VERSION "K24_Common"

NS_ :

BS_:

BU_: PCM UNKNOWN

BO_ 316 PCM_0x13C: 8 PCM
 SG_ TORQUE_ESTIMATE : 7|16@0- (1,0) [-32768|32767] "raw"  UNKNOWN
 SG_ TORQUE_TARGET : 23|16@0- (1,0) [-32768|32767] "raw"  UNKNOWN
 SG_ ACCELERATOR_REQUEST : 32|8@1+ (0.39215686274509803,0) [0|100] "%"  UNKNOWN
 SG_ TORQUE_STATE : 40|2@1+ (1,0) [0|3] ""  UNKNOWN
 SG_ RSVD_1 : 42|2@1+ (1,0) [0|3] ""  UNKNOWN
 SG_ UNKNOWN_1 : 44|1@1+ (1,0) [0|1] ""  UNKNOWN
 SG_ FRAME_1AA_WINDOW_LATCH : 45|1@1+ (1,0) [0|1] ""  UNKNOWN
 SG_ START_PHASE_LATCH : 46|1@1+ (1,0) [0|1] ""  UNKNOWN
 SG_ DTC_STATUS_7_LATCH : 47|1@1+ (1,0) [0|1] ""  UNKNOWN
 SG_ STOP_CONTACT_GUARD : 48|1@1+ (1,0) [0|1] ""  UNKNOWN
 SG_ RSVD_3 : 49|1@1+ (1,0) [0|1] ""  UNKNOWN
 SG_ CLUTCH_PEDAL_POSITION_SWITCH_B_STATUS : 50|1@1+ (1,0) [0|1] ""  UNKNOWN
 SG_ RSVD_4 : 51|5@1+ (1,0) [0|31] ""  UNKNOWN
 SG_ CHECKSUM : 56|4@1+ (1,0) [0|15] ""  UNKNOWN
 SG_ COUNTER : 60|2@1+ (1,0) [0|3] ""  UNKNOWN
 SG_ INITIALIZED_STATUS : 62|1@1+ (1,0) [0|1] ""  UNKNOWN
 SG_ FRAME_1AA_INVALID_OR_FALLBACK_STATE_TBD : 63|1@1+ (1,0) [0|1] ""  UNKNOWN
VAL_ 316 CLUTCH_PEDAL_POSITION_SWITCH_B_STATUS 0 "OPEN" 1 "CLOSE" ;
VAL_ 316 TORQUE_STATE 0 "NORMAL" 1 "VSA_CONTROL_CANDIDATE" 2 "FUEL_CUT" 3 "UNKNOWN" ;

CM_ SG_ 316 CLUTCH_PEDAL_POSITION_SWITCH_B_STATUS "CANFI: Clutch Pedal Position Switch B Status";
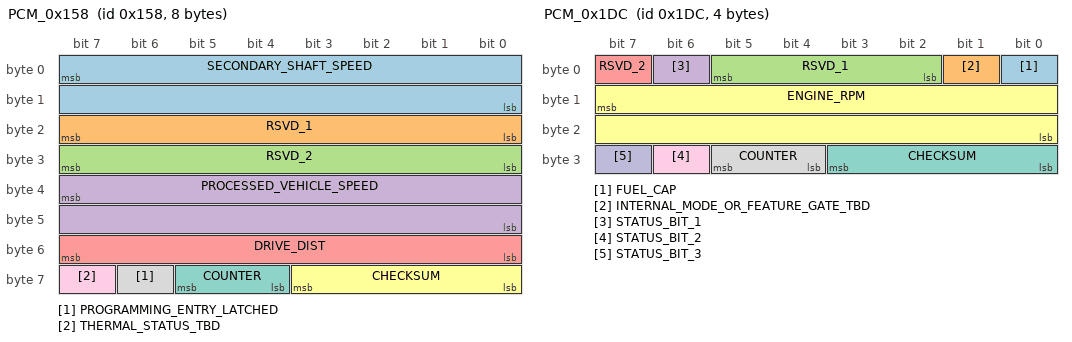
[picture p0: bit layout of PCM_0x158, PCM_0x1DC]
BO_ 344 PCM_0x158: 8 PCM
 SG_ SECONDARY_SHAFT_SPEED : 7|16@0+ (0.01,0) [0|655.35] "km/h"  UNKNOWN
 SG_ RSVD_1 : 16|8@1+ (1,0) [0|255] ""  UNKNOWN
 SG_ RSVD_2 : 24|8@1+ (1,0) [0|255] ""  UNKNOWN
 SG_ PROCESSED_VEHICLE_SPEED : 39|16@0+ (0.01,0) [0|655.35] "km/h"  UNKNOWN
 SG_ DRIVE_DIST : 48|8@1+ (10,0) [0|2550] "m"  UNKNOWN
 SG_ CHECKSUM : 56|4@1+ (1,0) [0|15] ""  UNKNOWN
 SG_ COUNTER : 60|2@1+ (1,0) [0|3] ""  UNKNOWN
 SG_ PROGRAMMING_ENTRY_LATCHED : 62|1@1+ (1,0) [0|1] ""  UNKNOWN
 SG_ THERMAL_STATUS_TBD : 63|1@1+ (1,0) [0|1] ""  UNKNOWN

CM_ SG_ 344 DRIVE_DIST "CANFI: Drive Dist";
BO_ 380 PCM_0x17C: 8 PCM
 SG_ ACCELERATOR_PEDAL_POSITION : 0|8@1+ (0.39215686274509803,0) [0|100] "%"  UNKNOWN
 SG_ THROTTLE_ABOVE_IDLE : 8|8@1+ (0.4,0) [0|102] "deg"  UNKNOWN
 SG_ ENGINE_SPEED : 23|16@0+ (1,0) [0|65535] "rpm"  UNKNOWN
 SG_ BRAKE_SWITCH : 32|1@1+ (1,0) [0|1] ""  UNKNOWN
 SG_ CRUISE_CANCEL_EVENT : 33|1@1+ (1,0) [0|1] ""  UNKNOWN
 SG_ CRUISE_FAULT_SPEED_INHIBIT : 34|1@1+ (1,0) [0|1] ""  UNKNOWN
 SG_ CRUISE_ENGAGED : 35|1@1+ (1,0) [0|1] ""  UNKNOWN
 SG_ MIL : 36|1@1+ (1,0) [0|1] ""  UNKNOWN
 SG_ MIL_STATUS : 37|1@1+ (1,0) [0|1] ""  UNKNOWN
 SG_ CRUISE_INDICATOR : 38|1@1+ (1,0) [0|1] ""  UNKNOWN
 SG_ GAS_PEDAL_PRESSED : 39|1@1+ (1,0) [0|1] ""  UNKNOWN
 SG_ RSVD_1 : 40|1@1+ (1,0) [0|1] ""  UNKNOWN
 SG_ APPLICATION_STATUS_ASSERTED : 41|1@1+ (1,0) [0|1] ""  UNKNOWN
 SG_ ACCEL_PEDAL_FAULT : 42|1@1+ (1,0) [0|1] ""  UNKNOWN
 SG_ RSVD_2 : 43|2@1+ (1,0) [0|3] ""  UNKNOWN
 SG_ IDLE_STOP_PRIMARY_CONTROL : 45|1@1+ (1,0) [0|1] ""  UNKNOWN
 SG_ IDLE_STOP_CST_CONTRIBUTION : 46|1@1+ (1,0) [0|1] ""  UNKNOWN
 SG_ ENGINE_IDLE_STOP_MODE_CONTROL : 47|1@1+ (1,0) [0|1] ""  UNKNOWN
 SG_ RSVD_3 : 48|5@1+ (1,0) [0|31] ""  UNKNOWN
 SG_ CRUISE_BRAKE_SW_IDLE_STOP_SW : 53|1@1+ (1,0) [0|1] ""  UNKNOWN
 SG_ CRUISE_TRANS_REQUEST_WIRE : 54|2@1+ (1,0) [0|3] ""  UNKNOWN
 SG_ CHECKSUM : 56|4@1+ (1,0) [0|15] ""  UNKNOWN
 SG_ COUNTER : 60|2@1+ (1,0) [0|3] ""  UNKNOWN
 SG_ RSVD_4 : 62|1@1+ (1,0) [0|1] ""  UNKNOWN
 SG_ FIWARN : 63|1@1+ (1,0) [0|1] ""  UNKNOWN
VAL_ 380 CRUISE_BRAKE_SW_IDLE_STOP_SW 0 "CLOSE" 1 "OPEN" ;
VAL_ 380 ENGINE_IDLE_STOP_MODE_CONTROL 0 "UNCONTROLLED" 1 "CONTROLLED" ;
VAL_ 380 CRUISE_INDICATOR 0 "OFF" 1 "ON" ;
VAL_ 380 MIL_STATUS 0 "OFF" 1 "ON" ;
VAL_ 380 MIL 0 "OFF" 1 "ON" ;
VAL_ 380 BRAKE_SWITCH 0 "OFF" 1 "ON" ;

CM_ SG_ 380 ENGINE_SPEED "CANFI: Engine Speed";
CM_ SG_ 380 BRAKE_SWITCH "CANFI: Brake Switch";
CM_ SG_ 380 MIL "CANFI: MIL";
CM_ SG_ 380 MIL_STATUS "CANFI: MIL Status";
CM_ SG_ 380 CRUISE_INDICATOR "CANFI: Cruise Indicator";
CM_ SG_ 380 CRUISE_BRAKE_SW_IDLE_STOP_SW "CANFI: Cruise Brake Sw/Idle Stop Sw";
CM_ SG_ 380 ENGINE_IDLE_STOP_MODE_CONTROL "CANFI: Engine Idle Stop Mode Control";
CM_ SG_ 380 FIWARN "CANFI: FIWARN";
BO_ 476 PCM_0x1DC: 4 PCM
 SG_ FUEL_CAP : 0|1@1+ (1,0) [0|1] ""  UNKNOWN
 SG_ INTERNAL_MODE_OR_FEATURE_GATE_TBD : 1|1@1+ (1,0) [0|1] ""  UNKNOWN
 SG_ RSVD_1 : 2|4@1+ (1,0) [0|15] ""  UNKNOWN
 SG_ STATUS_BIT_1 : 6|1@1+ (1,0) [0|1] ""  UNKNOWN
 SG_ RSVD_2 : 7|1@1+ (1,0) [0|1] ""  UNKNOWN
 SG_ ENGINE_RPM : 15|16@0+ (1,0) [0|65535] "rpm"  UNKNOWN
 SG_ CHECKSUM : 24|4@1+ (1,0) [0|15] ""  UNKNOWN
 SG_ COUNTER : 28|2@1+ (1,0) [0|3] ""  UNKNOWN
 SG_ STATUS_BIT_2 : 30|1@1+ (1,0) [0|1] ""  UNKNOWN
 SG_ STATUS_BIT_3 : 31|1@1+ (1,0) [0|1] ""  UNKNOWN
VAL_ 476 FUEL_CAP 0 "CLOSE" 1 "OPEN" ;

CM_ SG_ 476 FUEL_CAP "CANFI: FUEL CAP";
BO_ 800 PCM_0x320: 8 PCM
 SG_ RSVD_1 : 0|6@1+ (1,0) [0|63] ""  UNKNOWN
 SG_ ENGINE_STATE_TBD : 6|2@1+ (1,0) [0|3] ""  UNKNOWN
 SG_ STATUS_BIT_1 : 8|1@1+ (1,0) [0|1] ""  UNKNOWN
 SG_ STATUS_BIT_2 : 9|1@1+ (1,0) [0|1] ""  UNKNOWN
 SG_ RSVD_2 : 10|4@1+ (1,0) [0|15] ""  UNKNOWN
 SG_ I_VTEC_INDICATOR_COMMAND : 14|1@1+ (1,0) [0|1] ""  UNKNOWN
 SG_ RSVD_3 : 15|1@1+ (1,0) [0|1] ""  UNKNOWN
 SG_ UNKNOWN_1 : 16|3@1+ (1,0) [0|7] ""  UNKNOWN
 SG_ UNKNOWN_4 : 19|3@1+ (1,0) [0|7] ""  UNKNOWN
 SG_ STATUS_BIT_3 : 22|1@1+ (1,0) [0|1] ""  UNKNOWN
 SG_ STATUS_BIT_9_TBD : 23|1@1+ (1,0) [0|1] ""  UNKNOWN
 SG_ RSVD_4 : 24|8@1+ (1,0) [0|255] ""  UNKNOWN
 SG_ RSVD_5 : 32|7@1+ (1,0) [0|127] ""  UNKNOWN
 SG_ STATUS_BIT_4 : 39|1@1+ (1,0) [0|1] ""  UNKNOWN
 SG_ UNKNOWN_2 : 40|3@1+ (1,0) [0|7] ""  UNKNOWN
 SG_ UNKNOWN_3 : 43|3@1+ (1,0) [0|7] ""  UNKNOWN
 SG_ UNKNOWN_5 : 46|2@1+ (1,0) [0|3] ""  UNKNOWN
 SG_ STATUS_BIT_5 : 48|1@1+ (1,0) [0|1] ""  UNKNOWN
 SG_ RSVD_6 : 49|2@1+ (1,0) [0|3] ""  UNKNOWN
 SG_ STATUS_BIT_6 : 51|1@1+ (1,0) [0|1] ""  UNKNOWN
 SG_ RSVD_7 : 52|4@1+ (1,0) [0|15] ""  UNKNOWN
 SG_ CHECKSUM : 56|4@1+ (1,0) [0|15] ""  UNKNOWN
 SG_ COUNTER : 60|2@1+ (1,0) [0|3] ""  UNKNOWN
 SG_ STATUS_BIT_7 : 62|1@1+ (1,0) [0|1] ""  UNKNOWN
 SG_ STATUS_BIT_8 : 63|1@1+ (1,0) [0|1] ""  UNKNOWN
VAL_ 800 I_VTEC_INDICATOR_COMMAND 0 "OFF" 1 "ON" ;

CM_ SG_ 800 I_VTEC_INDICATOR_COMMAND "CANFI: i-VTEC Indicator Command";
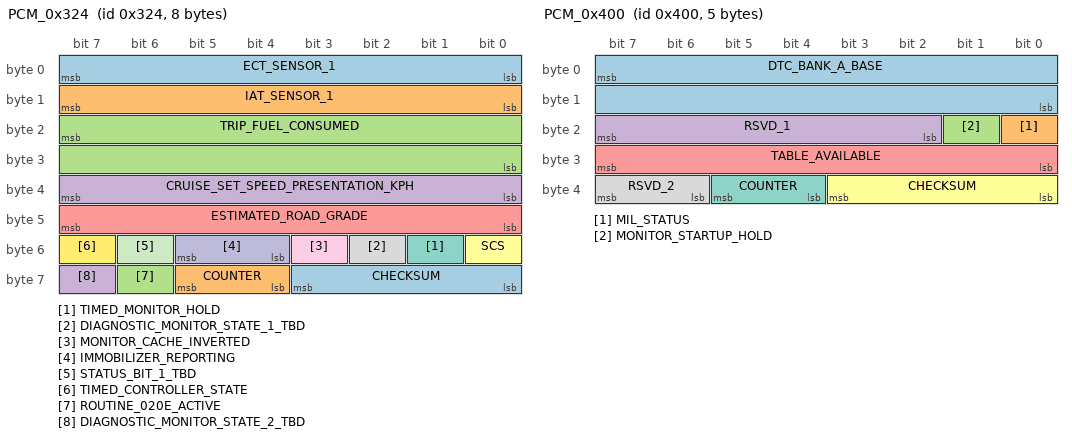
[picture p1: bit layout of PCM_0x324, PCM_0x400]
BO_ 804 PCM_0x324: 8 PCM
 SG_ ECT_SENSOR_1 : 0|8@1+ (1,-40) [-40|215] "degC"  UNKNOWN
 SG_ IAT_SENSOR_1 : 8|8@1+ (1,-40) [-40|215] "degC"  UNKNOWN
 SG_ TRIP_FUEL_CONSUMED : 23|16@0+ (1,0) [0|65535] ""  UNKNOWN
 SG_ CRUISE_SET_SPEED_PRESENTATION_KPH : 32|8@1+ (1,0) [0|255] "km/h"  UNKNOWN
 SG_ ESTIMATED_ROAD_GRADE : 40|8@1- (0.125,0) [-16|15.875] "%"  UNKNOWN
 SG_ SCS : 48|1@1+ (1,0) [0|1] ""  UNKNOWN
 SG_ TIMED_MONITOR_HOLD : 49|1@1+ (1,0) [0|1] ""  UNKNOWN
 SG_ DIAGNOSTIC_MONITOR_STATE_1_TBD : 50|1@1+ (1,0) [0|1] ""  UNKNOWN
 SG_ MONITOR_CACHE_INVERTED : 51|1@1+ (1,0) [0|1] ""  UNKNOWN
 SG_ IMMOBILIZER_REPORTING : 52|2@1+ (1,0) [0|3] ""  UNKNOWN
 SG_ STATUS_BIT_1_TBD : 54|1@1+ (1,0) [0|1] ""  UNKNOWN
 SG_ TIMED_CONTROLLER_STATE : 55|1@1+ (1,0) [0|1] ""  UNKNOWN
 SG_ CHECKSUM : 56|4@1+ (1,0) [0|15] ""  UNKNOWN
 SG_ COUNTER : 60|2@1+ (1,0) [0|3] ""  UNKNOWN
 SG_ ROUTINE_020E_ACTIVE : 62|1@1+ (1,0) [0|1] ""  UNKNOWN
 SG_ DIAGNOSTIC_MONITOR_STATE_2_TBD : 63|1@1+ (1,0) [0|1] ""  UNKNOWN
VAL_ 804 IMMOBILIZER_REPORTING 0 "COMPLETE_ACCEPTED" 1 "INCOMPLETE" 2 "COMPLETE_NOT_ACCEPTED" ;
VAL_ 804 SCS 0 "OPEN" 1 "SHORT" ;
VAL_ 804 IAT_SENSOR_1 255 "INVALID" ;
VAL_ 804 ECT_SENSOR_1 255 "INVALID" ;

CM_ SG_ 804 SCS "CANFI: SCS";
BO_ 808 PCM_0x328: 8 PCM
 SG_ RSVD_1 : 0|8@1+ (1,0) [0|255] ""  UNKNOWN
 SG_ IDLE_STOP_CVT_PREREQUISITE : 8|8@1+ (1,0) [0|255] ""  UNKNOWN
 SG_ RSVD_2 : 16|8@1+ (1,0) [0|255] ""  UNKNOWN
 SG_ RSVD_3 : 24|2@1+ (1,0) [0|3] ""  UNKNOWN
 SG_ STOCK_DISABLED_IDLE_STOP_PREREQUISITE : 26|1@1+ (1,0) [0|1] ""  UNKNOWN
 SG_ RSVD_4 : 27|5@1+ (1,0) [0|31] ""  UNKNOWN
 SG_ RSVD_5 : 32|8@1+ (1,0) [0|255] ""  UNKNOWN
 SG_ RSVD_6 : 40|2@1+ (1,0) [0|3] ""  UNKNOWN
 SG_ THROTTLE_ACTUATOR_SUPPLY_VOLTAGE_OFF_EVENT_TBD : 42|1@1+ (1,0) [0|1] ""  UNKNOWN
 SG_ STATUS_BIT_1 : 43|1@1+ (1,0) [0|1] ""  UNKNOWN
 SG_ SECONDARY_REQUEST_LIMIT_ENABLE : 44|1@1+ (1,0) [0|1] ""  UNKNOWN
 SG_ RSVD_7 : 45|1@1+ (1,0) [0|1] ""  UNKNOWN
 SG_ DISCRETE_INPUT_QUALIFICATION : 46|1@1+ (1,0) [0|1] ""  UNKNOWN
 SG_ STARTUP_QUALIFICATION_COMPLETE : 47|1@1+ (1,0) [0|1] ""  UNKNOWN
 SG_ CRUISE_TRANSITION_REASON : 48|4@1+ (1,0) [0|15] ""  UNKNOWN
 SG_ RSVD_8 : 52|2@1+ (1,0) [0|3] ""  UNKNOWN
 SG_ STATUS_BIT_2 : 54|1@1+ (1,0) [0|1] ""  UNKNOWN
 SG_ RSVD_9 : 55|1@1+ (1,0) [0|1] ""  UNKNOWN
 SG_ CHECKSUM : 56|4@1+ (1,0) [0|15] ""  UNKNOWN
 SG_ COUNTER : 60|2@1+ (1,0) [0|3] ""  UNKNOWN
 SG_ STATUS_BIT_3_TBD : 62|1@1+ (1,0) [0|1] ""  UNKNOWN
 SG_ ACCELERATOR_PEDAL_DUAL_TRACK_FAULT_ANY : 63|1@1+ (1,0) [0|1] ""  UNKNOWN

BO_ 1024 PCM_0x400: 5 PCM
 SG_ DTC_BANK_A_BASE : 7|16@0+ (1,0) [0|65535] ""  UNKNOWN
 SG_ MIL_STATUS : 16|1@1+ (1,0) [0|1] ""  UNKNOWN
 SG_ MONITOR_STARTUP_HOLD : 17|1@1+ (1,0) [0|1] ""  UNKNOWN
 SG_ RSVD_1 : 18|6@1+ (1,0) [0|63] ""  UNKNOWN
 SG_ TABLE_AVAILABLE : 24|8@1+ (1,0) [0|255] ""  UNKNOWN
 SG_ CHECKSUM : 32|4@1+ (1,0) [0|15] ""  UNKNOWN
 SG_ COUNTER : 36|2@1+ (1,0) [0|3] ""  UNKNOWN
 SG_ RSVD_2 : 38|2@1+ (1,0) [0|3] ""  UNKNOWN
VAL_ 1024 MIL_STATUS 0 "OFF" 1 "ON" ;

CM_ SG_ 1024 MIL_STATUS "CANFI: MIL Status";
BO_ 1036 PCM_0x40C: 8 PCM
 SG_ MULTIPLEX_PAGE M : 0|4@1+ (1,0) [0|15] ""  UNKNOWN
 SG_ MULTIPLEX_GROUP : 4|2@1+ (1,0) [0|3] ""  UNKNOWN
 SG_ DIAGNOSTIC_EVENT_STATE : 6|2@1+ (1,0) [0|3] ""  UNKNOWN
 SG_ RSVD_1 m0 : 8|8@1+ (1,0) [0|255] ""  UNKNOWN
 SG_ P01_VIN_CHARACTER_1_B1 m1 : 8|8@1+ (1,0) [0|255] ""  UNKNOWN
 SG_ P02_VIN_CHARACTER_7_B1 m2 : 8|8@1+ (1,0) [0|255] ""  UNKNOWN
 SG_ P03_VIN_CHARACTER_13_B1 m3 : 8|8@1+ (1,0) [0|255] ""  UNKNOWN
 SG_ P04_ECUID1 m4 : 8|8@1+ (1,0) [0|255] ""  UNKNOWN
 SG_ P05_ENGINE_SPEED m5 : 15|16@0+ (0.25,0) [0|16383.75] "rpm"  UNKNOWN
 SG_ P06_IAT_SENSOR_1_V m6 : 8|8@1+ (0.019600000232458115,0.0) [0|4.998000059276819] "V"  UNKNOWN
 SG_ P0B_HO2S_S2 m11 : 16|8@1+ (0.019600000232458115,0.0) [0|4.998000059276819] "V"  UNKNOWN
 SG_ P06_MAP_SENSOR_V m6 : 24|8@1+ (0.019600000232458115,0.0) [0|4.998000059276819] "V"  UNKNOWN
 SG_ P08_TP_SENSOR_A m8 : 24|8@1+ (0.019600000232458115,0.0) [0|4.998000059276819] "V"  UNKNOWN
 SG_ P08_TP_SENSOR_B m8 : 32|8@1+ (0.019600000232458115,0.0) [0|4.998000059276819] "V"  UNKNOWN
 SG_ P0D_MAF_SENSOR m13 : 32|8@1+ (0.019600000232458115,0.0) [0|4.998000059276819] "V"  UNKNOWN
 SG_ P05_ECT_SENSOR_1_V m5 : 40|8@1+ (0.019600000232458115,0.0) [0|4.998000059276819] "V"  UNKNOWN
 SG_ P06_BARO_SENSOR_V m6 : 40|8@1+ (0.019600000232458115,0.0) [0|4.998000059276819] "V"  UNKNOWN
 SG_ P07_APP_SENSOR_A m7 : 40|8@1+ (0.019600000232458115,0.0) [0|4.998000059276819] "V"  UNKNOWN
 SG_ P07_APP_SENSOR_B m7 : 48|8@1+ (0.019600000232458115,0.0) [0|4.998000059276819] "V"  UNKNOWN
 SG_ P07_VEHICLE_SPEED_PCM m7 : 8|8@1+ (1,0) [0|255] "km/h"  UNKNOWN
 SG_ P08_APP_SENSOR m8 : 15|16@0+ (0.005,0) [0|327.675] "%"  UNKNOWN
 SG_ P09_TARGET_TH_VLV m9 : 15|16@0+ (0.005,0) [0|327.675] "deg"  UNKNOWN
 SG_ RSVD_2 m10 : 8|8@1+ (1,0) [0|255] ""  UNKNOWN
 SG_ P0B_FSS m11 : 8|8@1+ (1,0) [0|255] ""  UNKNOWN
 SG_ RSVD_3 m12 : 8|8@1+ (1,0) [0|255] ""  UNKNOWN
 SG_ RSVD_4 m13 : 8|8@1+ (1,0) [0|255] ""  UNKNOWN
 SG_ P0E_MAF_SENSOR m14 : 15|16@0+ (0.01,0) [0|655.35] "g/s"  UNKNOWN
 SG_ P0F_FUEL_LEVEL m15 : 8|8@1+ (0.39215686274509803,0) [0|100] "%"  UNKNOWN
 SG_ P00_DIAGNOSTIC_EVENT_OR_FREEZE_DTC m0 : 23|16@0+ (1,0) [0|65535] ""  UNKNOWN
 SG_ P01_VIN_CHARACTER_2_B2 m1 : 16|8@1+ (1,0) [0|255] ""  UNKNOWN
 SG_ P02_VIN_CHARACTER_8_B2 m2 : 16|8@1+ (1,0) [0|255] ""  UNKNOWN
 SG_ P03_VIN_CHARACTER_14_B2 m3 : 16|8@1+ (1,0) [0|255] ""  UNKNOWN
 SG_ P04_ECUID2 m4 : 16|8@1+ (1,0) [0|255] ""  UNKNOWN
 SG_ P06_IAT_SENSOR_1_DEG_C m6 : 16|8@1+ (1,-40) [-40|215] "degC"  UNKNOWN
 SG_ P07_CLV m7 : 16|8@1+ (0.39215686274509803,0) [0|100] "%"  UNKNOWN
 SG_ RSVD_5 m10 : 16|8@1+ (1,0) [0|255] ""  UNKNOWN
 SG_ RSVD_6 m12 : 16|8@1+ (1,0) [0|255] ""  UNKNOWN
 SG_ P0D_AF_SENSOR m13 : 23|16@0+ (1,0) [0|65535] ""  UNKNOWN
 SG_ RSVD_7 m15 : 16|8@1+ (1,0) [0|255] ""  UNKNOWN
 SG_ P01_VIN_CHARACTER_3_B3 m1 : 24|8@1+ (1,0) [0|255] ""  UNKNOWN
 SG_ P02_VIN_CHARACTER_9_B3 m2 : 24|8@1+ (1,0) [0|255] ""  UNKNOWN
 SG_ P03_VIN_CHARACTER_15_B3 m3 : 24|8@1+ (1,0) [0|255] ""  UNKNOWN
 SG_ P04_ECUID3 m4 : 24|8@1+ (1,0) [0|255] ""  UNKNOWN
 SG_ P05_TP_SENSOR m5 : 24|8@1+ (0.39215686274509803,0) [0|100] "%"  UNKNOWN
 SG_ P07_SPARK_ADVANCE m7 : 24|8@1+ (0.5,-64) [-64|63.5] "deg"  UNKNOWN
 SG_ P09_THROTTLE_AN12_BASELINE m9 : 24|8@1+ (1,0) [0|255] ""  UNKNOWN
 SG_ P0A_AF_LAMBDA m10 : 31|16@0+ (3.0517578125e-05,0) [0|1.999969482421875] "ratio"  UNKNOWN
 SG_ RSVD_8 m11 : 24|8@1+ (1,0) [0|255] ""  UNKNOWN
 SG_ RSVD_9 m12 : 24|8@1+ (1,0) [0|255] ""  UNKNOWN
 SG_ P0E_CMP_CTRL m14 : 24|8@1+ (1,0) [0|255] ""  UNKNOWN
 SG_ RSVD_10 m15 : 24|8@1+ (1,0) [0|255] ""  UNKNOWN
 SG_ P00_FORMAT_OR_LENGTH m0 : 32|8@1+ (1,0) [0|255] ""  UNKNOWN
 SG_ P01_VIN_CHARACTER_4_B4 m1 : 32|8@1+ (1,0) [0|255] ""  UNKNOWN
 SG_ P02_VIN_CHARACTER_10_B4 m2 : 32|8@1+ (1,0) [0|255] ""  UNKNOWN
 SG_ P03_VIN_CHARACTER_16_B4 m3 : 32|8@1+ (1,0) [0|255] ""  UNKNOWN
 SG_ P04_ECUID4 m4 : 32|8@1+ (1,0) [0|255] ""  UNKNOWN
 SG_ P05_REL_TP_SENSOR m5 : 32|8@1+ (0.39215686274509803,0) [0|100] "%"  UNKNOWN
 SG_ P06_MAP_SENSOR_KPA m6 : 32|8@1+ (1,0) [0|255] "kPa"  UNKNOWN
 SG_ P07_CONTROL_MODULE_VOLTAGE_CLAMPED m7 : 32|8@1+ (1,0) [0|255] "raw"  UNKNOWN
 SG_ P09_THROTTLE_AN45_BASELINE m9 : 32|8@1+ (1,0) [0|255] ""  UNKNOWN
 SG_ RSVD_11 m11 : 32|8@1+ (1,0) [0|255] ""  UNKNOWN
 SG_ RSVD_12 m12 : 32|8@1+ (1,0) [0|255] ""  UNKNOWN
 SG_ P0E_ENGINE_RUNTIME m14 : 39|16@0+ (1,0) [0|65535] "s"  UNKNOWN
 SG_ RSVD_13 m15 : 32|8@1+ (1,0) [0|255] ""  UNKNOWN
 SG_ RSVD_14 m0 : 40|8@1+ (1,0) [0|255] ""  UNKNOWN
 SG_ P01_VIN_CHARACTER_5_B5 m1 : 40|8@1+ (1,0) [0|255] ""  UNKNOWN
 SG_ P02_VIN_CHARACTER_11_B5 m2 : 40|8@1+ (1,0) [0|255] ""  UNKNOWN
 SG_ P03_VIN_CHARACTER_17_B5 m3 : 40|8@1+ (1,0) [0|255] ""  UNKNOWN
 SG_ P04_ECUID5 m4 : 40|8@1+ (1,0) [0|255] ""  UNKNOWN
 SG_ P08_THROTTLE_VLV m8 : 47|16@0+ (0.005,0) [0|327.675] "deg"  UNKNOWN
 SG_ P09_IDLE_TARGET_TH m9 : 47|16@0+ (0.005,0) [0|327.675] "deg"  UNKNOWN
 SG_ P0A_AF_FB_ST_FUEL_TRIM m10 : 40|8@1+ (0.0078125,0) [0|1.9921875] "ratio"  UNKNOWN
 SG_ RSVD_15 m11 : 40|8@1+ (1,0) [0|255] ""  UNKNOWN
 SG_ P0C_F_INJECTOR m12 : 47|16@0+ (0.004,0) [0|262.14] "ms"  UNKNOWN
 SG_ P0D_AF_LAMBDA_CMD m13 : 47|16@0+ (3.0517578125e-05,0) [0|1.999969482421875] "ratio"  UNKNOWN
 SG_ RSVD_16 m15 : 40|8@1+ (1,0) [0|255] ""  UNKNOWN
 SG_ RSVD_17 m0 : 48|8@1+ (1,0) [0|255] ""  UNKNOWN
 SG_ P01_VIN_CHARACTER_6_B6 m1 : 48|8@1+ (1,0) [0|255] ""  UNKNOWN
 SG_ P02_VIN_CHARACTER_12_B6 m2 : 48|8@1+ (1,0) [0|255] ""  UNKNOWN
 SG_ P03_IDENTIFICATION_EXTRA_BYTE_TBD m3 : 48|8@1+ (1,0) [0|255] ""  UNKNOWN
 SG_ RSVD_18 m4 : 48|8@1+ (1,0) [0|255] ""  UNKNOWN
 SG_ P05_ECT_SENSOR_1_DEG_C m5 : 48|8@1+ (1,-40) [-40|215] "degC"  UNKNOWN
 SG_ P06_BARO_SENSOR_KPA m6 : 48|8@1+ (1,0) [0|255] "kPa"  UNKNOWN
 SG_ P0A_AF_FB_AVE_LT_FUEL_TRIM m10 : 48|8@1+ (0.0078125,0) [0|1.9921875] "ratio"  UNKNOWN
 SG_ RSVD_19 m11 : 48|8@1+ (1,0) [0|255] ""  UNKNOWN
 SG_ P0E_EVAP_PC_DUTY m14 : 48|8@1+ (0.39215686274509803,0) [0|100] "%"  UNKNOWN
 SG_ RSVD_20 m15 : 48|8@1+ (1,0) [0|255] ""  UNKNOWN
 SG_ CHECKSUM : 56|4@1+ (1,0) [0|15] ""  UNKNOWN
 SG_ COUNTER : 60|2@1+ (1,0) [0|3] ""  UNKNOWN
 SG_ DIAGNOSTIC_STATUS_FLAG_6 m0 : 62|1@1+ (1,0) [0|1] ""  UNKNOWN
 SG_ DIAGNOSTIC_STATUS_FLAG_7 m0 : 63|1@1+ (1,0) [0|1] ""  UNKNOWN
 SG_ RSVD_21 m5 : 62|2@1+ (1,0) [0|3] ""  UNKNOWN
VAL_ 1036 P0B_FSS 0 "NONE" 1 "OL_COND" 2 "CLOSED" 4 "OL_DRV" 8 "OL_DTC" 16 "CL_O2_SX" ;
SG_MUL_VAL_ 1036 RSVD_1 MULTIPLEX_PAGE 0-0;
SG_MUL_VAL_ 1036 P01_VIN_CHARACTER_1_B1 MULTIPLEX_PAGE 1-1;
SG_MUL_VAL_ 1036 P02_VIN_CHARACTER_7_B1 MULTIPLEX_PAGE 2-2;
SG_MUL_VAL_ 1036 P03_VIN_CHARACTER_13_B1 MULTIPLEX_PAGE 3-3;
SG_MUL_VAL_ 1036 P04_ECUID1 MULTIPLEX_PAGE 4-4;
SG_MUL_VAL_ 1036 P05_ENGINE_SPEED MULTIPLEX_PAGE 5-5;
SG_MUL_VAL_ 1036 P07_VEHICLE_SPEED_PCM MULTIPLEX_PAGE 7-7;
SG_MUL_VAL_ 1036 P08_APP_SENSOR MULTIPLEX_PAGE 8-8;
SG_MUL_VAL_ 1036 P09_TARGET_TH_VLV MULTIPLEX_PAGE 9-9;
SG_MUL_VAL_ 1036 RSVD_2 MULTIPLEX_PAGE 10-10;
SG_MUL_VAL_ 1036 P0B_FSS MULTIPLEX_PAGE 11-11;
SG_MUL_VAL_ 1036 RSVD_3 MULTIPLEX_PAGE 12-12;
SG_MUL_VAL_ 1036 RSVD_4 MULTIPLEX_PAGE 13-13;
SG_MUL_VAL_ 1036 P0E_MAF_SENSOR MULTIPLEX_PAGE 14-14;
SG_MUL_VAL_ 1036 P0F_FUEL_LEVEL MULTIPLEX_PAGE 15-15;
SG_MUL_VAL_ 1036 P00_DIAGNOSTIC_EVENT_OR_FREEZE_DTC MULTIPLEX_PAGE 0-0;
SG_MUL_VAL_ 1036 P01_VIN_CHARACTER_2_B2 MULTIPLEX_PAGE 1-1;
SG_MUL_VAL_ 1036 P02_VIN_CHARACTER_8_B2 MULTIPLEX_PAGE 2-2;
SG_MUL_VAL_ 1036 P03_VIN_CHARACTER_14_B2 MULTIPLEX_PAGE 3-3;
SG_MUL_VAL_ 1036 P04_ECUID2 MULTIPLEX_PAGE 4-4;
SG_MUL_VAL_ 1036 P06_IAT_SENSOR_1_DEG_C MULTIPLEX_PAGE 6-6;
SG_MUL_VAL_ 1036 P07_CLV MULTIPLEX_PAGE 7-7;
SG_MUL_VAL_ 1036 RSVD_5 MULTIPLEX_PAGE 10-10;
SG_MUL_VAL_ 1036 RSVD_6 MULTIPLEX_PAGE 12-12;
SG_MUL_VAL_ 1036 P0D_AF_SENSOR MULTIPLEX_PAGE 13-13;
SG_MUL_VAL_ 1036 RSVD_7 MULTIPLEX_PAGE 15-15;
SG_MUL_VAL_ 1036 P01_VIN_CHARACTER_3_B3 MULTIPLEX_PAGE 1-1;
SG_MUL_VAL_ 1036 P02_VIN_CHARACTER_9_B3 MULTIPLEX_PAGE 2-2;
SG_MUL_VAL_ 1036 P03_VIN_CHARACTER_15_B3 MULTIPLEX_PAGE 3-3;
SG_MUL_VAL_ 1036 P04_ECUID3 MULTIPLEX_PAGE 4-4;
SG_MUL_VAL_ 1036 P05_TP_SENSOR MULTIPLEX_PAGE 5-5;
SG_MUL_VAL_ 1036 P07_SPARK_ADVANCE MULTIPLEX_PAGE 7-7;
SG_MUL_VAL_ 1036 P09_THROTTLE_AN12_BASELINE MULTIPLEX_PAGE 9-9;
SG_MUL_VAL_ 1036 P0A_AF_LAMBDA MULTIPLEX_PAGE 10-10;
SG_MUL_VAL_ 1036 RSVD_8 MULTIPLEX_PAGE 11-11;
SG_MUL_VAL_ 1036 RSVD_9 MULTIPLEX_PAGE 12-12;
SG_MUL_VAL_ 1036 P0E_CMP_CTRL MULTIPLEX_PAGE 14-14;
SG_MUL_VAL_ 1036 RSVD_10 MULTIPLEX_PAGE 15-15;
SG_MUL_VAL_ 1036 P00_FORMAT_OR_LENGTH MULTIPLEX_PAGE 0-0;
SG_MUL_VAL_ 1036 P01_VIN_CHARACTER_4_B4 MULTIPLEX_PAGE 1-1;
SG_MUL_VAL_ 1036 P02_VIN_CHARACTER_10_B4 MULTIPLEX_PAGE 2-2;
SG_MUL_VAL_ 1036 P03_VIN_CHARACTER_16_B4 MULTIPLEX_PAGE 3-3;
SG_MUL_VAL_ 1036 P04_ECUID4 MULTIPLEX_PAGE 4-4;
SG_MUL_VAL_ 1036 P05_REL_TP_SENSOR MULTIPLEX_PAGE 5-5;
SG_MUL_VAL_ 1036 P06_MAP_SENSOR_KPA MULTIPLEX_PAGE 6-6;
SG_MUL_VAL_ 1036 P07_CONTROL_MODULE_VOLTAGE_CLAMPED MULTIPLEX_PAGE 7-7;
SG_MUL_VAL_ 1036 P09_THROTTLE_AN45_BASELINE MULTIPLEX_PAGE 9-9;
SG_MUL_VAL_ 1036 RSVD_11 MULTIPLEX_PAGE 11-11;
SG_MUL_VAL_ 1036 RSVD_12 MULTIPLEX_PAGE 12-12;
SG_MUL_VAL_ 1036 P0E_ENGINE_RUNTIME MULTIPLEX_PAGE 14-14;
SG_MUL_VAL_ 1036 RSVD_13 MULTIPLEX_PAGE 15-15;
SG_MUL_VAL_ 1036 RSVD_14 MULTIPLEX_PAGE 0-0;
SG_MUL_VAL_ 1036 P01_VIN_CHARACTER_5_B5 MULTIPLEX_PAGE 1-1;
SG_MUL_VAL_ 1036 P02_VIN_CHARACTER_11_B5 MULTIPLEX_PAGE 2-2;
SG_MUL_VAL_ 1036 P03_VIN_CHARACTER_17_B5 MULTIPLEX_PAGE 3-3;
SG_MUL_VAL_ 1036 P04_ECUID5 MULTIPLEX_PAGE 4-4;
SG_MUL_VAL_ 1036 P08_THROTTLE_VLV MULTIPLEX_PAGE 8-8;
SG_MUL_VAL_ 1036 P09_IDLE_TARGET_TH MULTIPLEX_PAGE 9-9;
SG_MUL_VAL_ 1036 P0A_AF_FB_ST_FUEL_TRIM MULTIPLEX_PAGE 10-10;
SG_MUL_VAL_ 1036 RSVD_15 MULTIPLEX_PAGE 11-11;
SG_MUL_VAL_ 1036 P0C_F_INJECTOR MULTIPLEX_PAGE 12-12;
SG_MUL_VAL_ 1036 P0D_AF_LAMBDA_CMD MULTIPLEX_PAGE 13-13;
SG_MUL_VAL_ 1036 RSVD_16 MULTIPLEX_PAGE 15-15;
SG_MUL_VAL_ 1036 RSVD_17 MULTIPLEX_PAGE 0-0;
SG_MUL_VAL_ 1036 P01_VIN_CHARACTER_6_B6 MULTIPLEX_PAGE 1-1;
SG_MUL_VAL_ 1036 P02_VIN_CHARACTER_12_B6 MULTIPLEX_PAGE 2-2;
SG_MUL_VAL_ 1036 P03_IDENTIFICATION_EXTRA_BYTE_TBD MULTIPLEX_PAGE 3-3;
SG_MUL_VAL_ 1036 RSVD_18 MULTIPLEX_PAGE 4-4;
SG_MUL_VAL_ 1036 P05_ECT_SENSOR_1_DEG_C MULTIPLEX_PAGE 5-5;
SG_MUL_VAL_ 1036 P06_BARO_SENSOR_KPA MULTIPLEX_PAGE 6-6;
SG_MUL_VAL_ 1036 P0A_AF_FB_AVE_LT_FUEL_TRIM MULTIPLEX_PAGE 10-10;
SG_MUL_VAL_ 1036 RSVD_19 MULTIPLEX_PAGE 11-11;
SG_MUL_VAL_ 1036 P0E_EVAP_PC_DUTY MULTIPLEX_PAGE 14-14;
SG_MUL_VAL_ 1036 RSVD_20 MULTIPLEX_PAGE 15-15;

CM_ SG_ 1036 P05_ENGINE_SPEED "CANFI: Engine Speed";
CM_ SG_ 1036 P05_TP_SENSOR "CANFI: TP Sensor";
CM_ SG_ 1036 P05_REL_TP_SENSOR "CANFI: REL TP Sensor";
CM_ SG_ 1036 P05_ECT_SENSOR_1_DEG_C "CANFI: ECT Sensor 1";
CM_ SG_ 1036 P06_IAT_SENSOR_1_DEG_C "CANFI: IAT Sensor (1)";
CM_ SG_ 1036 P06_MAP_SENSOR_KPA "CANFI: MAP Sensor";
CM_ SG_ 1036 P06_BARO_SENSOR_KPA "CANFI: Baro Sensor";
CM_ SG_ 1036 P07_VEHICLE_SPEED_PCM "CANFI: Vehicle Speed(PCM)";
CM_ SG_ 1036 P07_SPARK_ADVANCE "CANFI: Spark Advance";
CM_ SG_ 1036 P08_APP_SENSOR "CANFI: APP Sensor";
CM_ SG_ 1036 P08_THROTTLE_VLV "CANFI: Throttle VLV";
CM_ SG_ 1036 P09_TARGET_TH_VLV "CANFI: Target TH VLV";
CM_ SG_ 1036 P09_IDLE_TARGET_TH "CANFI: Idle Target TH";
CM_ SG_ 1036 P0A_AF_LAMBDA "CANFI: AF Lambda";
CM_ SG_ 1036 P0A_AF_FB_ST_FUEL_TRIM "CANFI: AF FB (ST Fuel Trim)";
CM_ SG_ 1036 P0A_AF_FB_AVE_LT_FUEL_TRIM "CANFI: AF FB AVE (LT Fuel Trim)";
CM_ SG_ 1036 P0C_F_INJECTOR "CANFI: F Injector";
CM_ SG_ 1036 P0D_AF_SENSOR "CANFI: AF Sensor";
CM_ SG_ 1036 P0D_AF_LAMBDA_CMD "CANFI: AF Lambda Cmd";
CM_ SG_ 1036 P0E_MAF_SENSOR "CANFI: MAF Sensor";
CM_ SG_ 1036 P0E_CMP_CTRL "CANFI: CMP Ctrl";
CM_ SG_ 1036 P0E_EVAP_PC_DUTY "CANFI: EVAP PC Duty";
CM_ SG_ 1036 P0F_FUEL_LEVEL "CANFI: Fuel Level";
CM_ SG_ 1036 P04_ECUID1 "CANFI: ECUID1";
CM_ SG_ 1036 P04_ECUID2 "CANFI: ECUID2";
CM_ SG_ 1036 P04_ECUID3 "CANFI: ECUID3";
CM_ SG_ 1036 P04_ECUID4 "CANFI: ECUID4";
CM_ SG_ 1036 P04_ECUID5 "CANFI: ECUID5";
CM_ SG_ 1036 P07_CLV "CANFI: CLV";
CM_ SG_ 1036 P0B_FSS "CANFI: FSS";
SG_MUL_VAL_ 1036 DIAGNOSTIC_STATUS_FLAG_6 MULTIPLEX_PAGE 0-4;
SG_MUL_VAL_ 1036 DIAGNOSTIC_STATUS_FLAG_7 MULTIPLEX_PAGE 0-4;
SG_MUL_VAL_ 1036 RSVD_21 MULTIPLEX_PAGE 5-15;
CM_ SG_ 1036 P06_IAT_SENSOR_1_V "CANFI: IAT Sensor (1)";
CM_ SG_ 1036 P0B_HO2S_S2 "CANFI: HO2S S2";
CM_ SG_ 1036 P06_MAP_SENSOR_V "CANFI: MAP Sensor";
CM_ SG_ 1036 P08_TP_SENSOR_A "CANFI: TP Sensor A";
CM_ SG_ 1036 P08_TP_SENSOR_B "CANFI: TP Sensor B";
CM_ SG_ 1036 P0D_MAF_SENSOR "CANFI: MAF Sensor";
CM_ SG_ 1036 P05_ECT_SENSOR_1_V "CANFI: ECT Sensor 1";
CM_ SG_ 1036 P06_BARO_SENSOR_V "CANFI: Baro Sensor";
CM_ SG_ 1036 P07_APP_SENSOR_A "CANFI: APP Sensor A";
CM_ SG_ 1036 P07_APP_SENSOR_B "CANFI: APP Sensor B";
BO_ 1108 PCM_0x454: 8 PCM
 SG_ RETAINED_MODEL_QUANTITY : 0|8@1+ (1,0) [0|255] ""  UNKNOWN
 SG_ BARO_SENSOR : 8|8@1+ (1,0) [0|255] ""  UNKNOWN
 SG_ UNKNOWN_1 : 16|4@1+ (1,0) [0|15] ""  UNKNOWN
 SG_ BAROMETRIC_SENSOR_FAULT_AGGREGATE : 20|1@1+ (1,0) [0|1] ""  UNKNOWN
 SG_ SIGNED_STATE_BIT_5 : 21|1@1+ (1,0) [0|1] ""  UNKNOWN
 SG_ MODEL_HOLD_ACTIVE : 22|1@1+ (1,0) [0|1] ""  UNKNOWN
 SG_ STATUS_BIT_1 : 23|1@1+ (1,0) [0|1] ""  UNKNOWN
 SG_ SCALED_MODEL_QUANTITY : 31|16@0+ (1,0) [0|65535] ""  UNKNOWN
 SG_ RSVD_1 : 40|8@1+ (1,0) [0|255] ""  UNKNOWN
 SG_ ELECTRICAL_MONITOR_SECONDARY : 48|1@1+ (1,0) [0|1] ""  UNKNOWN
 SG_ STATUS_BIT_2 : 49|1@1+ (1,0) [0|1] ""  UNKNOWN
 SG_ STATUS_BIT_3 : 50|1@1+ (1,0) [0|1] ""  UNKNOWN
 SG_ ELECTRICAL_MONITOR_PRIMARY : 51|1@1+ (1,0) [0|1] ""  UNKNOWN
 SG_ RSVD_2 : 52|1@1+ (1,0) [0|1] ""  UNKNOWN
 SG_ POST_CRANK_CONTROL_LATCH : 53|1@1+ (1,0) [0|1] ""  UNKNOWN
 SG_ VARIANT_MATCH : 54|1@1+ (1,0) [0|1] ""  UNKNOWN
 SG_ MONITOR_HOLD : 55|1@1+ (1,0) [0|1] ""  UNKNOWN
 SG_ CHECKSUM : 56|4@1+ (1,0) [0|15] ""  UNKNOWN
 SG_ COUNTER : 60|2@1+ (1,0) [0|3] ""  UNKNOWN
 SG_ RSVD_3 : 62|2@1+ (1,0) [0|3] ""  UNKNOWN
